AUTOSAR XML (schema 4-2-2)
package /ComponentTypes
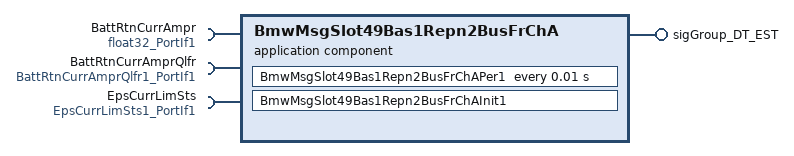
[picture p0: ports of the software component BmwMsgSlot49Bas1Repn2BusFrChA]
  application sw component type BmwMsgSlot49Bas1Repn2BusFrChA
    provide port sigGroup_DT_EST: nonqueued-sender-com-spec{data-element=sigGroup_DT_EST, uses-end-to-end-protection=true, init-value=fields=[ST_CULL_EST:0, DT_EST_dummy_64_95:0, QU_AVL_I_ACT_EST:14, DT_EST_dummy_12_15:0, AVL_I_ACT_EST:0, ALIV_DT_EST:15, CRC_DT_EST:0, DT_EST_dummy_96_127:0, DT_EST_dummy_16_46:0]}, provided-interface=sigGroup_DT_EST
    require port BattRtnCurrAmpr: nonqueued-receiver-com-spec{data-element=Val, filter=data-filter-type=ALWAYS, init-value=0}, required-interface=float32_PortIf1
    require port BattRtnCurrAmprQlfr: nonqueued-receiver-com-spec{data-element=Val, filter=data-filter-type=ALWAYS, init-value=15}, required-interface=BattRtnCurrAmprQlfr1_PortIf1
    require port EpsCurrLimSts: nonqueued-receiver-com-spec{data-element=Val, filter=data-filter-type=ALWAYS, init-value=15}, required-interface=EpsCurrLimSts1_PortIf1
    behavior BmwMsgSlot49Bas1Repn2BusFrChA_InternalBehavior
      init event BmwMsgSlot49Bas1Repn2BusFrChA_InitEvent: start-on-event=BmwMsgSlot49Bas1Repn2BusFrChAInit1
      timing event TMT_BmwMsgSlot49Bas1Repn2BusFrChA_Per1: start-on-event=BmwMsgSlot49Bas1Repn2BusFrChAPer1, period=0.01
      port-api-options:
        enable-take-address=false, error-handling=NO-TRANSFORMER-ERROR-HANDLING, indirect-api=false, port=BattRtnCurrAmpr
        enable-take-address=false, error-handling=NO-TRANSFORMER-ERROR-HANDLING, indirect-api=false, port=BattRtnCurrAmprQlfr
        enable-take-address=false, error-handling=NO-TRANSFORMER-ERROR-HANDLING, indirect-api=false, port=EpsCurrLimSts
        enable-take-address=false, error-handling=NO-TRANSFORMER-ERROR-HANDLING, indirect-api=false, port=sigGroup_DT_EST
      runnable BmwMsgSlot49Bas1Repn2BusFrChAInit1
      runnable BmwMsgSlot49Bas1Repn2BusFrChAPer1
        data-receive-point-by-arguments:
          access REC_BattRtnCurrAmpr_Val: accessed-variable=BattRtnCurrAmpr.Val
          access REC_BattRtnCurrAmprQlfr_Val: accessed-variable=BattRtnCurrAmprQlfr.Val
          access REC_EpsCurrLimSts_Val: accessed-variable=EpsCurrLimSts.Val
        data-send-points:
          access SEND_sigGroup_DT_EST_sigGroup_DT_EST: accessed-variable=sigGroup_DT_EST.sigGroup_DT_EST
  swc implementation BmwMsgSlot49Bas1Repn2BusFrChA_Implementation: behavior=BmwMsgSlot49Bas1Repn2BusFrChA_InternalBehavior
    code-descriptors:
      code Default: artifact-descriptors=autosar-engineering-object={short-label=Default, category=SWSRC}
